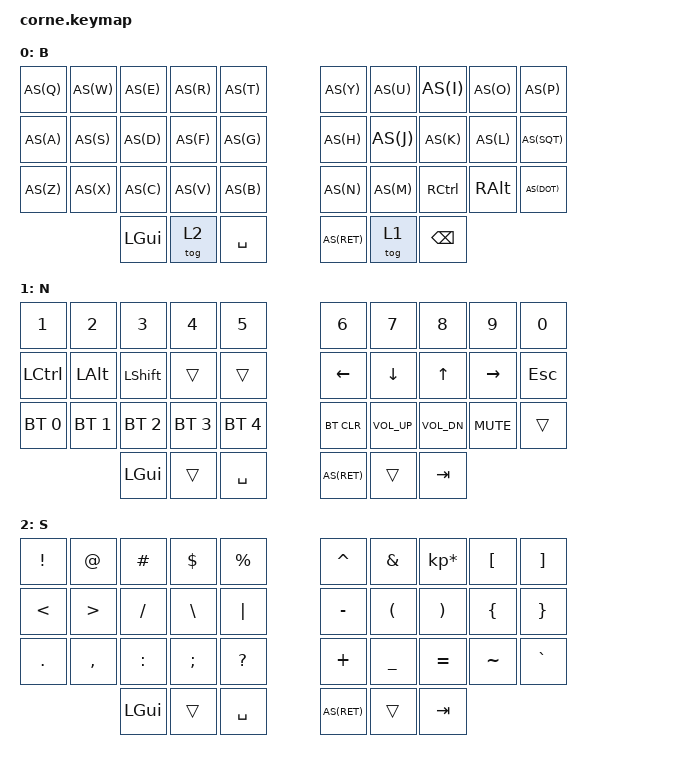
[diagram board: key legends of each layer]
/*
 * Copyright (c) 2020 The ZMK Contributors
 *
 * SPDX-License-Identifier: MIT
 */

#include <behaviors.dtsi>
#include <dt-bindings/zmk/keys.h>
#include <dt-bindings/zmk/bt.h>


#define AS(keycode) &as LS(keycode) keycode

/ {
    chosen {
        zmk,physical-layout = &foostan_corne_5col_layout;
    };

    behaviors {
        as: auto_shift {
            compatible = "zmk,behavior-hold-tap";
            #binding-cells = <2>;
            tapping_term_ms = <200>;
            quick_tap_ms = <0>;
            flavor = "tap-preferred";
            bindings = <&kp>, <&kp>;
        };
    };
        keymap {
                compatible = "zmk,keymap";

                default_layer {
// -----------------------------------------------------------------------------------------
// |  Q  |  W  |  E  |  R  |  T  |     |  Y  |  U   |  I   |  O   | P |
// |  A  |  S  |  D  |  F  |  G  |     |  H  |  J   |  K   |  L   | ' | 
// |  Z  |  X  |  C  |  V  |  B  |     |  N  |  M   | CTRL | META | . |
//             | GUI | LWR | SPC |     | ENT | RSE  | BSPC |
                        display-name = "B";
                        bindings = <
   AS(Q) AS(W) AS(E) AS(R) AS(T)     AS(Y)   AS(U)  AS(I)     AS(O)     AS(P)
   AS(A) AS(S) AS(D) AS(F) AS(G)     AS(H)   AS(J)  AS(K)     AS(L)     AS(SQT)
   AS(Z) AS(X) AS(C) AS(V) AS(B)     AS(N)   AS(M)  &kp RCTL  &kp RALT  AS(DOT)
        &kp LGUI &tog 2 &kp SPACE     AS(RET) &tog 1  &kp BSPC
                        >;
                };

                lower_layer {
// -----------------------------------------------------------------------------------------
// | 1     |  2   |  3     |  4  |  5  |     |  6    |  7  |  8  |  9  |  0  |
// | CTRL  | META | SHIFT  |     |     |     | LFT   | DWN |  UP | RGT | ESC |
// | BT1   | BT2  | BT3    | BT4 | BT5 |     | BTCLR |     |     |     |     |
//                | GUI    |     | SPC |     | ENT   |     | TAB |
                        display-name = "N";
                        bindings = <
   &kp N1       &kp N2       &kp N3       &kp N4       &kp N5           &kp N6      &kp N7        &kp N8         &kp N9         &kp N0
   &kp LCTL     &kp LALT     &kp LSHIFT   &trans       &trans           &kp LEFT    &kp DOWN      &kp UP         &kp RIGHT      &kp ESC
   &bt BT_SEL 0 &bt BT_SEL 1 &bt BT_SEL 2 &bt BT_SEL 3 &bt BT_SEL 4     &bt BT_CLR  &kp K_VOL_UP  &kp K_VOL_DN   &kp K_MUTE     &trans
                             &kp LGUI     &trans       &kp SPACE        AS(RET)     &trans  &kp TAB
                        >;
                };

                raise_layer {
// -----------------------------------------------------------------------------------------
// | !  |  @  |  #  |  $  |  %  |     |  ^  |  &  |  *  |  [   |  ]   |
// | <  |  >  |  /  |  \  |  |  |     |  -  |  (  |  )  |  {   |  }   |
// | .  |  ,  |  :  |  ;  |  ?  |     |  +  |  _  |  =  |  ~   |  `   |
//            | GUI |     | SPC |     | ENT |     | TAB |
                        display-name = "S";
                        bindings = <
   &kp EXCL  &kp AT    &kp HASH  &kp DLLR  &kp PRCNT     &kp CARET &kp AMPS   &kp KP_MULTIPLY &kp LBKT  &kp RBKT
   &kp LT    &kp GT    &kp FSLH  &kp BSLH  &kp PIPE      &kp MINUS &kp LPAR   &kp RPAR        &kp LBRC  &kp RBRC
   &kp DOT   &kp COMMA &kp COLON &kp SEMI  &kp QMARK     &kp PLUS  &kp UNDER  &kp EQUAL       &kp TILDE &kp GRAVE
                       &kp LGUI  &trans    &kp SPACE     AS(RET)   &trans     &kp TAB
                        >;
                };

                extra_1 {
                        status = "reserved";
                };

                extra_2 {
                        status = "reserved";
                };

                extra_3 {
                        status = "reserved";
                };
        };
};
